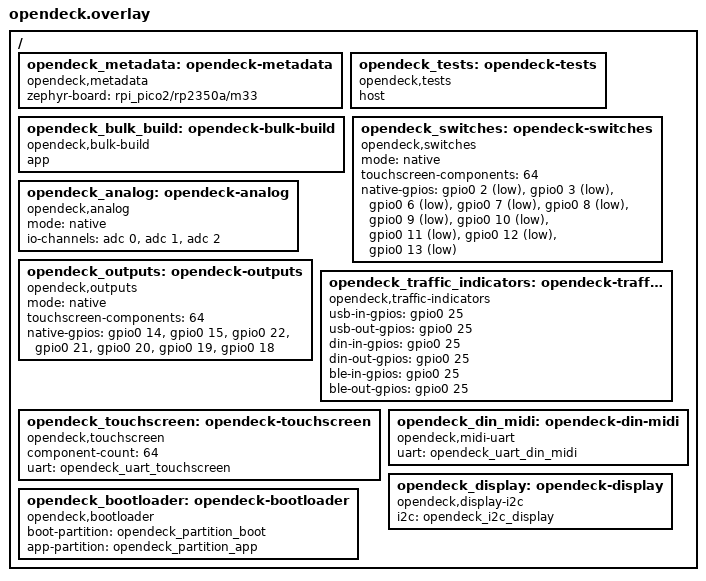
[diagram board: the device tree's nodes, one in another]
/ {
    opendeck_metadata: opendeck-metadata {
        compatible = "opendeck,metadata";
        zephyr-board = "rpi_pico2/rp2350a/m33";
    };

    opendeck_tests: opendeck-tests {
        compatible = "opendeck,tests";
        host;
    };

    opendeck_bulk_build: opendeck-bulk-build {
        compatible = "opendeck,bulk-build";
        app;
    };

    opendeck_switches: opendeck-switches {
        compatible = "opendeck,switches";
        mode = "native";
        touchscreen-components = <64>;
        native-gpios =
            <&gpio0 2 (GPIO_PULL_UP | GPIO_ACTIVE_LOW)>,
            <&gpio0 3 (GPIO_PULL_UP | GPIO_ACTIVE_LOW)>,
            <&gpio0 6 (GPIO_PULL_UP | GPIO_ACTIVE_LOW)>,
            <&gpio0 7 (GPIO_PULL_UP | GPIO_ACTIVE_LOW)>,
            <&gpio0 8 (GPIO_PULL_UP | GPIO_ACTIVE_LOW)>,
            <&gpio0 9 (GPIO_PULL_UP | GPIO_ACTIVE_LOW)>,
            <&gpio0 10 (GPIO_PULL_UP | GPIO_ACTIVE_LOW)>,
            <&gpio0 11 (GPIO_PULL_UP | GPIO_ACTIVE_LOW)>,
            <&gpio0 12 (GPIO_PULL_UP | GPIO_ACTIVE_LOW)>,
            <&gpio0 13 (GPIO_PULL_UP | GPIO_ACTIVE_LOW)>;
    };

    opendeck_analog: opendeck-analog {
        compatible = "opendeck,analog";
        mode = "native";
        io-channels =
            <&adc 0>,
            <&adc 1>,
            <&adc 2>;
    };

    opendeck_outputs: opendeck-outputs {
        compatible = "opendeck,outputs";
        mode = "native";
        touchscreen-components = <64>;
        native-gpios =
            <&gpio0 14 GPIO_ACTIVE_HIGH>,
            <&gpio0 15 GPIO_ACTIVE_HIGH>,
            <&gpio0 22 GPIO_ACTIVE_HIGH>,
            <&gpio0 21 GPIO_ACTIVE_HIGH>,
            <&gpio0 20 GPIO_ACTIVE_HIGH>,
            <&gpio0 19 GPIO_ACTIVE_HIGH>,
            <&gpio0 18 GPIO_ACTIVE_HIGH>;
    };

    opendeck_traffic_indicators: opendeck-traffic-indicators {
        compatible = "opendeck,traffic-indicators";
        usb-in-gpios = <&gpio0 25 GPIO_ACTIVE_HIGH>;
        usb-out-gpios = <&gpio0 25 GPIO_ACTIVE_HIGH>;
        din-in-gpios = <&gpio0 25 GPIO_ACTIVE_HIGH>;
        din-out-gpios = <&gpio0 25 GPIO_ACTIVE_HIGH>;
        ble-in-gpios = <&gpio0 25 GPIO_ACTIVE_HIGH>;
        ble-out-gpios = <&gpio0 25 GPIO_ACTIVE_HIGH>;
    };

    opendeck_touchscreen: opendeck-touchscreen {
        compatible = "opendeck,touchscreen";
        component-count = <64>;
        uart = <&opendeck_uart_touchscreen>;
    };

    opendeck_din_midi: opendeck-din-midi {
        compatible = "opendeck,midi-uart";
        uart = <&opendeck_uart_din_midi>;
    };

    opendeck_display: opendeck-display {
        compatible = "opendeck,display-i2c";
        i2c = <&opendeck_i2c_display>;
    };

    opendeck_bootloader: opendeck-bootloader {
        compatible = "opendeck,bootloader";
        boot-partition = <&opendeck_partition_boot>;
        app-partition = <&opendeck_partition_app>;
    };
};
